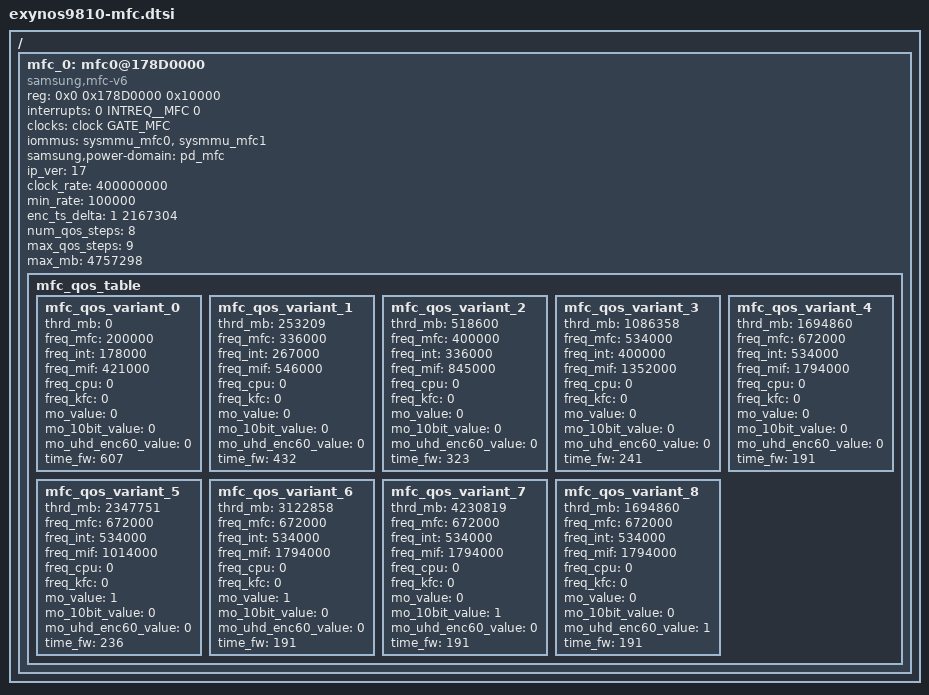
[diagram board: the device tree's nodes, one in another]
/*
 * SAMSUNG EXYNOS9810 SoC device tree source
 *
 * Copyright (c) 2017 Samsung Electronics Co., Ltd.
 *		http://www.samsung.com
 *
 * SAMSUNG EXYNOS9810 SoC device nodes are listed in this file.
 * EXYNOS9810 based board files can include this file and provide
 * values for board specfic bindings.
 *
 * This program is free software; you can redistribute it and/or modify
 * it under the terms of the GNU General Public License version 2 as
 * published by the Free Software Foundation.
 */

/ {
	mfc_0: mfc0@178D0000 {
		compatible = "samsung,mfc-v6";
		reg = <0x0 0x178D0000 0x10000>;
		interrupts = <0 INTREQ__MFC 0>;
		clock-names = "aclk_mfc";
		clocks = <&clock GATE_MFC>;
		iommus = <&sysmmu_mfc0>, <&sysmmu_mfc1>;
		samsung,power-domain = <&pd_mfc>;
		status = "ok";
		ip_ver = <17>;
		clock_rate = <400000000>;
		min_rate = <100000>;
		enc_ts_delta = <1 2167304>;
		num_qos_steps = <8>;
		max_qos_steps = <9>;
		max_mb = <4757298>;
		mfc_qos_table {
			mfc_qos_variant_0 {
				thrd_mb = <0>;
				freq_mfc = <200000>;
				freq_int = <178000>;
				freq_mif = <421000>;
				freq_cpu = <0>;
				freq_kfc = <0>;
				mo_value = <0>;
				mo_10bit_value = <0>;
				mo_uhd_enc60_value = <0>;
				time_fw = <607>;
			};
			mfc_qos_variant_1 {
				thrd_mb = <253209>;
				freq_mfc = <336000>;
				freq_int = <267000>;
				freq_mif = <546000>;
				freq_cpu = <0>;
				freq_kfc = <0>;
				mo_value = <0>;
				mo_10bit_value = <0>;
				mo_uhd_enc60_value = <0>;
				time_fw = <432>;
			};
			mfc_qos_variant_2 {
				thrd_mb = <518600>;
				freq_mfc = <400000>;
				freq_int = <336000>;
				freq_mif = <845000>;
				freq_cpu = <0>;
				freq_kfc = <0>;
				mo_value = <0>;
				mo_10bit_value = <0>;
				mo_uhd_enc60_value = <0>;
				time_fw = <323>;
			};
			mfc_qos_variant_3 {
				thrd_mb = <1086358>;
				freq_mfc = <534000>;
				freq_int = <400000>;
				freq_mif = <1352000>;
				freq_cpu = <0>;
				freq_kfc = <0>;
				mo_value = <0>;
				mo_10bit_value = <0>;
				mo_uhd_enc60_value = <0>;
				time_fw = <241>;
			};
			mfc_qos_variant_4 {
				thrd_mb = <1694860>;
				freq_mfc = <672000>;
				freq_int = <534000>;
				freq_mif = <1794000>;
				freq_cpu = <0>;
				freq_kfc = <0>;
				mo_value = <0>;
				mo_10bit_value = <0>;
				mo_uhd_enc60_value = <0>;
				time_fw = <191>;
			};
			mfc_qos_variant_5 {
				thrd_mb = <2347751>;
				freq_mfc = <672000>;
				freq_int = <534000>;
				freq_mif = <1014000>;
				freq_cpu = <0>;
				freq_kfc = <0>;
				mo_value = <1>;
				mo_10bit_value = <0>;
				mo_uhd_enc60_value = <0>;
				time_fw = <236>;
			};
			mfc_qos_variant_6 {
				thrd_mb = <3122858>;
				freq_mfc = <672000>;
				freq_int = <534000>;
				freq_mif = <1794000>;
				freq_cpu = <0>;
				freq_kfc = <0>;
				mo_value = <1>;
				mo_10bit_value = <0>;
				mo_uhd_enc60_value = <0>;
				time_fw = <191>;
			};
			mfc_qos_variant_7 {
				thrd_mb = <4230819>;
				freq_mfc = <672000>;
				freq_int = <534000>;
				freq_mif = <1794000>;
				freq_cpu = <0>;
				freq_kfc = <0>;
				mo_value = <0>;
				mo_10bit_value = <1>;
				mo_uhd_enc60_value = <0>;
				time_fw = <191>;
			};
			/* special level for uhd 60fps enc */
			mfc_qos_variant_8 {
				thrd_mb = <1694860>;
				freq_mfc = <672000>;
				freq_int = <534000>;
				freq_mif = <1794000>;
				freq_cpu = <0>;
				freq_kfc = <0>;
				mo_value = <0>;
				mo_10bit_value = <0>;
				mo_uhd_enc60_value = <1>;
				time_fw = <191>;
		};     };
	};
};
